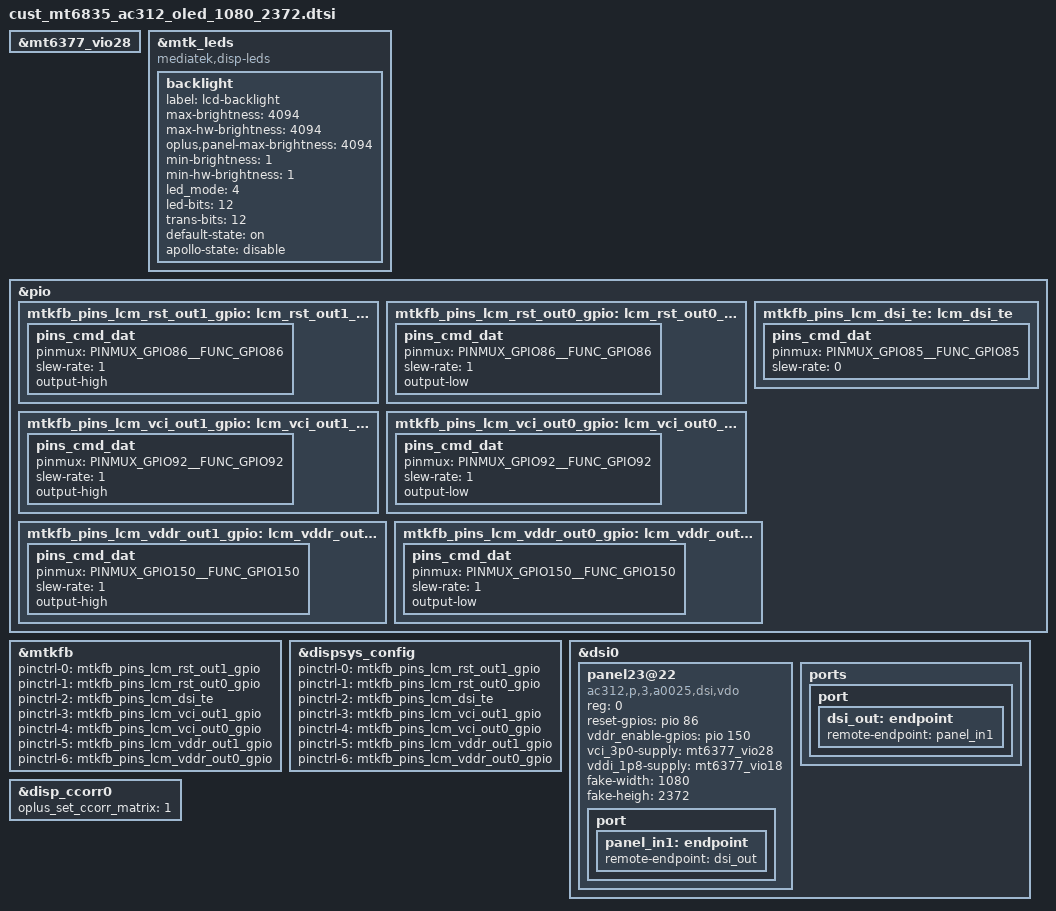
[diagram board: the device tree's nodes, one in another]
&mt6377_vio28 {
	/delete-property/ regulator-always-on;
};

&mtk_leds {
	compatible = "mediatek,disp-leds";

	backlight {
		label = "lcd-backlight";
		max-brightness = <4094>;
		max-hw-brightness = <4094>;
		oplus,panel-max-brightness=<4094>;
		min-brightness = <1>;
		min-hw-brightness = <1>;
		led_mode = <4>;
		led-bits = <12>;
		trans-bits = <12>;
		default-state = "on";
		apollo-state = "disable";
	};
};

&pio {
    mtkfb_pins_lcm_rst_out1_gpio: lcm_rst_out1_gpio {
        pins_cmd_dat {
            pinmux = <PINMUX_GPIO86__FUNC_GPIO86>;
            slew-rate = <1>;
            output-high;
        };
    };

    mtkfb_pins_lcm_rst_out0_gpio: lcm_rst_out0_gpio {
        pins_cmd_dat {
            pinmux = <PINMUX_GPIO86__FUNC_GPIO86>;
            slew-rate = <1>;
            output-low;
        };
    };

    mtkfb_pins_lcm_dsi_te: lcm_dsi_te {
        pins_cmd_dat {
            pinmux = <PINMUX_GPIO85__FUNC_GPIO85>;
            slew-rate = <0>;
        };
    };

    mtkfb_pins_lcm_vci_out1_gpio: lcm_vci_out1_gpio {
        pins_cmd_dat {
            pinmux = <PINMUX_GPIO92__FUNC_GPIO92>;
            slew-rate = <1>;
            output-high;
        };
    };

    mtkfb_pins_lcm_vci_out0_gpio: lcm_vci_out0_gpio {
        pins_cmd_dat {
            pinmux = <PINMUX_GPIO92__FUNC_GPIO92>;
            slew-rate = <1>;
            output-low;
        };
    };

    mtkfb_pins_lcm_vddr_out1_gpio: lcm_vddr_out1_gpio {
        pins_cmd_dat {
            pinmux = <PINMUX_GPIO150__FUNC_GPIO150>;
            slew-rate = <1>;
            output-high;
        };
    };

    mtkfb_pins_lcm_vddr_out0_gpio: lcm_vddr_out0_gpio {
        pins_cmd_dat {
            pinmux = <PINMUX_GPIO150__FUNC_GPIO150>;
            slew-rate = <1>;
            output-low;
        };
    };
};

&mtkfb {
    pinctrl-names = "lcm_rst_out1_gpio", "lcm_rst_out0_gpio",
        "mode_te_te", "lcm_vci_out1_gpio",
        "lcm_vci_out0_gpio", "lcm_vddr_out1_gpio",
        "lcm_vddr_out0_gpio", "lcm_vddi_out1_gpio",
        "lcm_vddi_out0_gpio";
    pinctrl-0 = <&mtkfb_pins_lcm_rst_out1_gpio>;
    pinctrl-1 = <&mtkfb_pins_lcm_rst_out0_gpio>;
    pinctrl-2 = <&mtkfb_pins_lcm_dsi_te>;
    pinctrl-3 = <&mtkfb_pins_lcm_vci_out1_gpio>;
    pinctrl-4 = <&mtkfb_pins_lcm_vci_out0_gpio>;
    pinctrl-5 = <&mtkfb_pins_lcm_vddr_out1_gpio>;
    pinctrl-6 = <&mtkfb_pins_lcm_vddr_out0_gpio>;
    status = "okay";
};

&dispsys_config {
    pinctrl-names = "lcm_rst_out1_gpio", "lcm_rst_out0_gpio",
        "mode_te_te", "lcm_vci_out1_gpio",
        "lcm_vci_out0_gpio", "lcm_vddr_out1_gpio",
        "lcm_vddr_out0_gpio", "lcm_vddi_out1_gpio",
        "lcm_vddi_out0_gpio";
    pinctrl-0 = <&mtkfb_pins_lcm_rst_out1_gpio>;
    pinctrl-1 = <&mtkfb_pins_lcm_rst_out0_gpio>;
    pinctrl-2 = <&mtkfb_pins_lcm_dsi_te>;
    pinctrl-3 = <&mtkfb_pins_lcm_vci_out1_gpio>;
    pinctrl-4 = <&mtkfb_pins_lcm_vci_out0_gpio>;
    pinctrl-5 = <&mtkfb_pins_lcm_vddr_out1_gpio>;
    pinctrl-6 = <&mtkfb_pins_lcm_vddr_out0_gpio>;
    status = "okay";
};

&dsi0 {
    status = "okay";
    #address-cells = <1>;
    #size-cells = <0>;
    panel23@22 {
        compatible = "ac312,p,3,a0025,dsi,vdo";
        reg = <0>;
        reset-gpios = <&pio 86 0>;
        vddr_enable-gpios = <&pio 150 0>;
        vci_3p0-supply = <&mt6377_vio28>;
        vddi_1p8-supply = <&mt6377_vio18>;
		fake-width = <1080>;
		fake-heigh = <2372>;
        pinctrl-names = "default";
        port {
            panel_in1: endpoint {
                remote-endpoint = <&dsi_out>;
            };
        };
    };
    ports {
        port {
            dsi_out: endpoint {
                remote-endpoint = <&panel_in1>;
            };
        };
    };
};

&disp_ccorr0 {
    oplus_set_ccorr_matrix = <1>;
};

#include "mediatek/cust_evb6835.dtsi"
